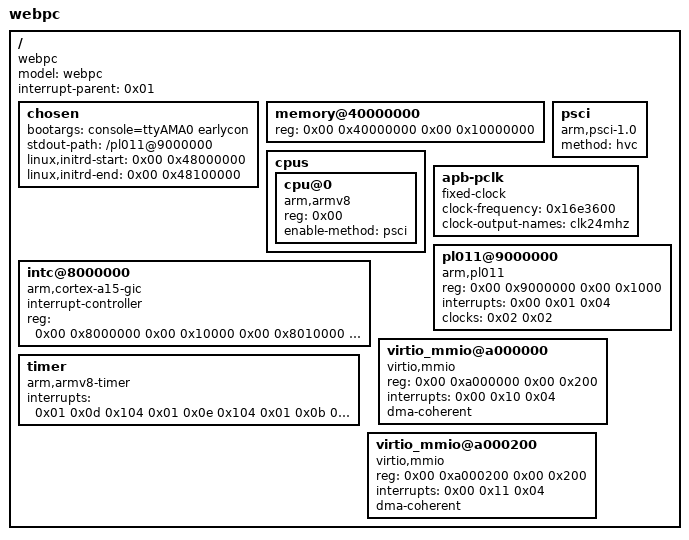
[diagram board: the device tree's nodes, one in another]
/dts-v1/;

/ {
	#address-cells = <0x02>;
	#size-cells = <0x02>;
	compatible = "webpc", "linux,dummy-virt";
	model = "webpc";
	interrupt-parent = <0x01>;

	chosen {
		bootargs = "console=ttyAMA0 earlycon";
		stdout-path = "/pl011@9000000";
		linux,initrd-start = <0x00 0x48000000>;
		linux,initrd-end = <0x00 0x48100000>;
	};

	memory@40000000 {
		device_type = "memory";
		reg = <0x00 0x40000000 0x00 0x10000000>;
	};

	cpus {
		#address-cells = <0x01>;
		#size-cells = <0x00>;

		cpu@0 {
			device_type = "cpu";
			compatible = "arm,armv8";
			reg = <0x00>;
			enable-method = "psci";
		};
	};

	psci {
		compatible = "arm,psci-1.0", "arm,psci-0.2";
		method = "hvc";
	};

	intc@8000000 {
		compatible = "arm,cortex-a15-gic";
		#interrupt-cells = <0x03>;
		interrupt-controller;
		reg = <0x00 0x8000000 0x00 0x10000 0x00 0x8010000 0x00 0x10000>;
		phandle = <0x01>;
	};

	timer {
		compatible = "arm,armv8-timer";
		interrupts = <0x01 0x0d 0x104 0x01 0x0e 0x104 0x01 0x0b 0x104 0x01 0x0a 0x104>;
	};

	apb-pclk {
		compatible = "fixed-clock";
		#clock-cells = <0x00>;
		clock-frequency = <0x16e3600>;
		clock-output-names = "clk24mhz";
		phandle = <0x02>;
	};

	pl011@9000000 {
		compatible = "arm,pl011", "arm,primecell";
		reg = <0x00 0x9000000 0x00 0x1000>;
		interrupts = <0x00 0x01 0x04>;
		clocks = <0x02 0x02>;
		clock-names = "uartclk", "apb_pclk";
	};

	virtio_mmio@a000000 {
		compatible = "virtio,mmio";
		reg = <0x00 0xa000000 0x00 0x200>;
		interrupts = <0x00 0x10 0x04>;
		dma-coherent;
	};

	virtio_mmio@a000200 {
		compatible = "virtio,mmio";
		reg = <0x00 0xa000200 0x00 0x200>;
		interrupts = <0x00 0x11 0x04>;
		dma-coherent;
	};
};
